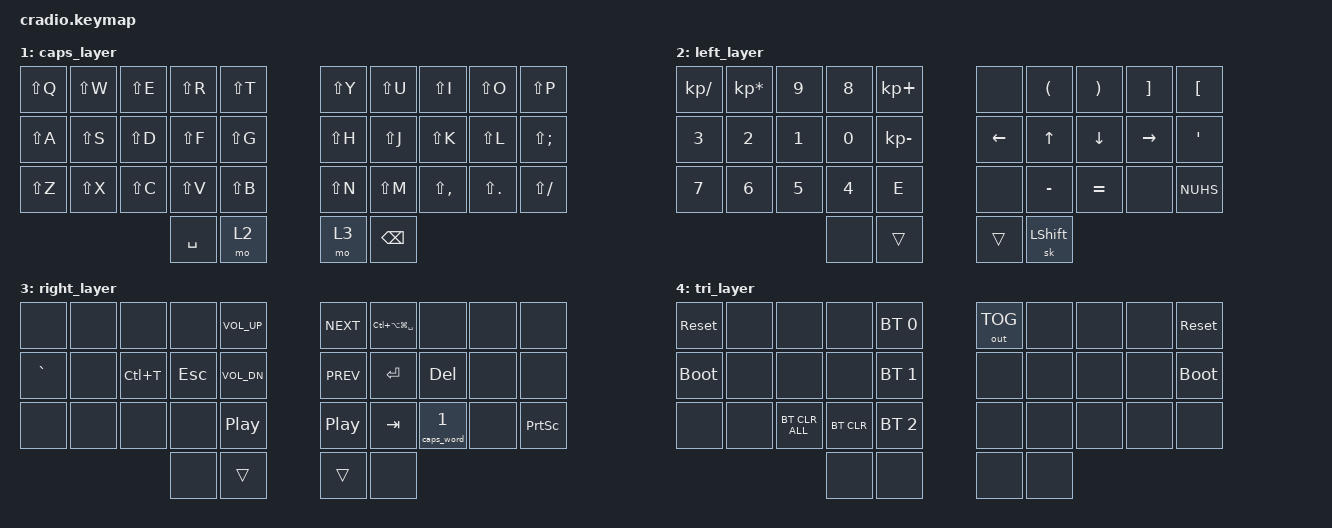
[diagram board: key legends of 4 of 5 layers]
// Copyright (c) 2022 The ZMK Contributors
// SPDX-License-Identifier: MIT

#include <behaviors.dtsi>
#include <dt-bindings/zmk/keys.h>
#include <dt-bindings/zmk/bt.h>
#include <dt-bindings/zmk/outputs.h>
#include <behaviors/num_word.dtsi>
#include "zmk-helpers/helper.h"

// Home row mods macro
// #define HRML(k1,k2,k3,k4) &ht LALT k1  &ht LGUI k2  &ht LCTRL k3  &ht LSHIFT k4
// #define HRMR(k1,k2,k3,k4) &ht RSHIFT k1  &ht LCTRL k2  &ht RGUI k3  &ht LALT k4

#define HRML(k1,k2,k3,k4) &hml LALT k1  &hml LGUI k2  &hml LCTRL k3  &hml LSHIFT k4
#define HRMR(k1,k2,k3,k4) &hmr RSHIFT k1  &hmr LCTRL k2  &hmr RGUI k3  &hmr LALT k4

#define KEYS_R 5 6 7 8 9 15 16 17 18 19 25 26 27 28 29
#define KEYS_L 0 1 2 3 4 10 11 12 13 14 20 21 22 23 24  
#define THUMBS 30 31 32 33 

#define LANG_SW &kp LC(LA(LG(SPACE)))

ZMK_HOLD_TAP(hml,
    flavor = "balanced";
    tapping-term-ms = <210>;
    quick-tap-ms = <175>;
    require-prior-idle-ms = <100>;
    bindings = <&kp>, <&kp>;
    hold-trigger-key-positions = <KEYS_R THUMBS>;
    hold-trigger-on-release;
)

ZMK_HOLD_TAP(hmr,
    flavor = "balanced";
    tapping-term-ms = <210>;
    quick-tap-ms = <175>;
    require-prior-idle-ms = <100>;
    bindings = <&kp>, <&kp>;
    hold-trigger-key-positions = <KEYS_L THUMBS>;
    hold-trigger-on-release;
)

// / {
//     combos {
//         compatible = "zmk,combos";
// 									// T (qwerty) = Y (dvorak)
//         combo_nvim_accept { timeout-ms = <50>; key-positions = <6 7>; bindings = <&kp LC(T)>; };
//     };
// };

&sk {
    release-after-ms = <800>;
    quick-release;
};

/ {
    behaviors {
        ht: positional_hold_tap {
            compatible = "zmk,behavior-hold-tap";
            #binding-cells = <2>;
            flavor = "tap-preferred";
            tapping-term-ms = <150>;
            quick-tap-ms = <100>;
            bindings = <&kp>, <&kp>;
        };

        sk_layer: sticky_shift_layer {
            compatible = "zmk,behavior-hold-tap";
            #binding-cells = <2>;
            tapping-term-ms = <110>;
            flavor = "tap-preferred";
            bindings = <&mo>, <&sk>;
        };

        caps_word: caps_word {
            compatible = "zmk,behavior-auto-layer";
            #binding-cells = <1>;
            continue-list = <Q W E R T Y U I O P A S D F G H J K L SEMI Z X C V B N M COMMA DOT SLASH BSPC DEL APOSTROPHE>;
            ignore-numbers;
            ignore-modifiers;
        };
    };

    conditional_layers {
        compatible = "zmk,conditional-layers";
        tri_layer {
            if-layers = <2 3>;
            then-layer = <4>;
        };
    };

    keymap {
        compatible = "zmk,keymap";
        default_layer {
            bindings = <
        //╭──────────┬──────────┬──────────┬──────────┬──────────╮   ╭──────────┬──────────┬──────────┬──────────┬──────────╮
        //│  Q       │  W       │  E       │  R       │  T       │   │  Y       │  U       │  I       │  O       │  P       │
            &kp Q      &kp W      &kp E      &kp R      &kp T          &kp Y      &kp U      &kp I      &kp O      &kp P
        //├──────────┼──────────┼──────────┼──────────┼──────────┤   ├──────────┼──────────┼──────────┼──────────┼──────────┤
        //│  A       │  S       │  D       │  F       │  G       │   │  H       │  J       │  K       │  L       │ ' "      │
            HRML(A,        S,         D,         F)     &kp G          &kp H      HRMR(J,        K,         L,        SEMI)
        //├──────────┼──────────┼──────────┼──────────┼──────────┤   ├──────────┼──────────┼──────────┼──────────┼──────────┤
        //│  Z       │  X       │  C       │  V       │  B       │   │  N       │  M       │ , <      │ . >      │ / ?      │
            &kp Z      &kp X      &kp C      &kp V      &kp B          &kp N      &kp M      &kp COMMA  &kp DOT    &kp FSLH
        //╰──────────┴──────────┴──────────┼──────────┼──────────┤   ├──────────┼──────────┼──────────┴──────────┴──────────╯
                                             &kp SPACE  &mo 2          &mo 3      &kp BSPC
        //                                 ╰──────────┴──────────╯   ╰──────────┴──────────╯
            >;
        };

        caps_layer {
            bindings = <
        //╭──────────┬──────────┬──────────┬──────────┬──────────╮   ╭──────────┬──────────┬──────────┬──────────┬──────────╮
        //│  Q       │  W       │  E       │  R       │  T       │   │  Y       │  U       │  I       │  O       │  P       │
            &kp LS(Q)  &kp LS(W)  &kp LS(E)  &kp LS(R)  &kp LS(T)      &kp LS(Y)  &kp LS(U)  &kp LS(I)  &kp LS(O)  &kp LS(P)
        //├──────────┼──────────┼──────────┼──────────┼──────────┤   ├──────────┼──────────┼──────────┼──────────┼──────────┤
        //│  A       │  S       │  D       │  F       │  G       │   │  H       │  J       │  K       │  L       │ ' "      │
            &kp LS(A)  &kp LS(S)  &kp LS(D)  &kp LS(F)  &kp LS(G)      &kp LS(H)  &kp LS(J)  &kp LS(K)  &kp LS(L)  &kp LS(SEMI)  
        //├──────────┼──────────┼──────────┼──────────┼──────────┤   ├──────────┼──────────┼──────────┼──────────┼──────────┤
        //│  Z       │  X       │  C       │  V       │  B       │   │  N       │  M       │ , <      │ . >      │ / ?      │
            &kp LS(Z)  &kp LS(X)  &kp LS(C)  &kp LS(V)  &kp LS(B)      &kp LS(N)  &kp LS(M)  &kp LS(COMMA) &kp LS(DOT) &kp LS(FSLH)
        //╰──────────┴──────────┴──────────┼──────────┼──────────┤   ├──────────┼──────────┼──────────┴──────────┴──────────╯
                                            &kp SPACE   &mo 2           &mo 3     &kp BSPC
        //                                 ╰──────────┴──────────╯   ╰──────────┴──────────╯
            >;
        };

        left_layer {
            bindings = <
        //╭──────────┬──────────┬──────────┬──────────┬──────────╮   ╭──────────┬──────────┬──────────┬──────────┬──────────╮
        //│          │          │          │          │          │   │          │    (     │    )     │    =+    │   /?     │
         &kp KP_DIVIDE &kp KP_MULTIPLY &kp N9 &kp N8   &kp KP_PLUS      &none     &kp LPAR   &kp RPAR   &kp RBKT   &kp LBKT 
        //├──────────┼──────────┼──────────┼──────────┼──────────┤   ├──────────┼──────────┼──────────┼──────────┼──────────┤
        //│          │          │          │          │          │   │          │          │          │          │    -_    │
             &kp N3     &kp N2     &kp N1     &kp N0  &kp KP_MINUS     &kp LEFT    &kp UP    &kp DOWN   &kp RIGHT  &kp APOS 
        //├──────────┼──────────┼──────────┼──────────┼──────────┤   ├──────────┼──────────┼──────────┼──────────┼──────────┤
        //│          │          │          │          │   (dot)  │   │          │    {[    │    ]}    │          │    \|    │
             &kp N7     &kp N6     &kp N5     &kp N4     &kp E          &none   &kp MINUS  &kp EQUAL    &none    &kp NUHS
        //╰──────────┴──────────┴──────────┼──────────┼──────────┤   ├──────────┼──────────┼──────────┴──────────┴──────────╯
                                               &none     &trans         &trans   &sk LSHIFT 
        //                                 ╰──────────┴──────────╯   ╰──────────┴──────────╯
            >;
        };

        right_layer {
            bindings = <
        //╭──────────┬──────────┬──────────┬──────────┬──────────╮   ╭──────────┬──────────┬──────────┬──────────┬──────────╮
        //│          │          │          │          │   VOL+   │   │   NEXT   │LNG_SWITCH│          │          │          │
             &none      &none      &none      &none   &kp C_VOL_UP    &kp C_NEXT  LANG_SW     &none      &none      &none 
        //├──────────┼──────────┼──────────┼──────────┼──────────┤   ├──────────┼──────────┼──────────┼──────────┼──────────┤
        //│          │          │          │          │   VOL-   │   │   PREV   │          │          │          │          │
            &kp GRAVE   &none    &kp LC(T)   &kp ESC  &kp C_VOL_DN   &kp C_PREV   &kp ENTER   &kp DEL    &none      &none 
        //├──────────┼──────────┼──────────┼──────────┼──────────┤   ├──────────┼──────────┼──────────┼──────────┼──────────┤
        //│          │          │          │          │PLAY/PAUSE│   │PLAY/PAUSE│          │CAPS_WORD │          │ PRNTSCRN │
             &none      &none      &none      &none     &kp C_PP       &kp C_PP   &kp TAB   &caps_word 1 &none     &kp PSCRN
        //╰──────────┴──────────┴──────────┼──────────┼──────────┤   ├──────────┼──────────┼──────────┴──────────┴──────────╯
                                              &none      &trans         &trans     &none 
        //                                 ╰──────────┴──────────╯   ╰──────────┴──────────╯
            >;
        };

        tri_layer {
            bindings = <
        //╭──────────┬──────────┬──────────┬──────────┬──────────╮   ╭──────────┬──────────┬──────────┬──────────┬──────────╮
        //│          │          │          │          │PROFILE 0 │   │ BLE_USB  │          │          │          │          │
           &sys_reset  &none      &none      &none     &bt BT_SEL 0  &out OUT_TOG &none      &none      &none     &sys_reset
        //├──────────┼──────────┼──────────┼──────────┼──────────┤   ├──────────┼──────────┼──────────┼──────────┼──────────┤
        //│          │          │          │          │PROFILE 1 │   │          │          │          │          │          │
          &bootloader  &none      &none      &none     &bt BT_SEL 1    &none      &none      &none      &none     &bootloader
        //├──────────┼──────────┼──────────┼──────────┼──────────┤   ├──────────┼──────────┼──────────┼──────────┼──────────┤
        //│          │          │          │          │PROFILE 2 │   │          │          │          │          │          │
            &none      &none    &bt BT_CLR_ALL &bt BT_CLR &bt BT_SEL 2 &none     &none      &none      &none      &none 
        //╰──────────┴──────────┴──────────┼──────────┼──────────┤   ├──────────┼──────────┼──────────┴──────────┴──────────╯
                                             &none      &none          &none      &none 
        //                                 ╰──────────┴──────────╯   ╰──────────┴──────────╯
            >;
        };

    };
};
